# NUC400_v1 register map
File version: 1.0
Registers are 32-bit, read-write, reset 0x0 unless marked. A register's access mark holds for its fields unless they carry their own. Offsets are from the block's base; [hi:lo] are bit positions.

## CAP — CAP Register Map
Base 0x40030000
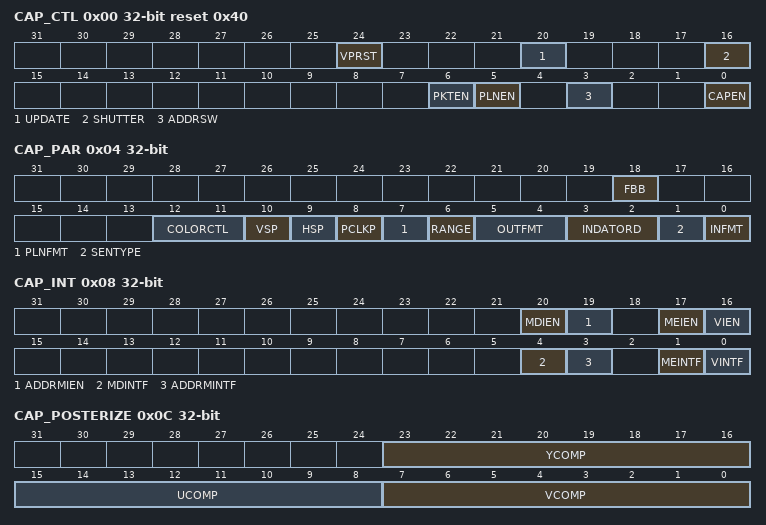
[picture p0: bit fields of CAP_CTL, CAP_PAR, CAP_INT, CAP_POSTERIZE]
0x00 CAP_CTL reset 0x40 — Image Capture Interface Control Register
  [24] VPRST — Capture Interface Reset
    0=Capture interface reset Disabled; 1=Capture interface reset Enabled
  [20] UPDATE — Update Register At New Frame
    0=Update register at new frame Disabled; 1=Update register at new frame Enabled (Auto clear to 0 when register updated)
  [16] SHUTTER — Image Capture Interface Automatically Disable The Capture Inteface After A Frame Had Been Captured
    0=Shutter Disabled; 1=Shutter Enabled
  [6] PKTEN — Packet Output Enable
    0=Packet output Disabled; 1=Packet output Enabled
  [5] PLNEN — Planar Output Enable
    0=Planar output Disabled; 1=Planar output Enabled
  [3] ADDRSW — Packet Buffer Address Switch
    0=Packet buffer address switch Disabled; 1=Packet buffer address switch Enabled
  [0] CAPEN — Image Capture Interface Enable
    0=Image Capture Interface Disabled; 1=Image Capture Interface Enabled
0x04 CAP_PAR — Image Capture Interface Parameter Register
  [18] FBB — Field By Blank. Hardware will tag field0 or field1 by vertical blanking instead of FIELD flag in ccir-656 mode.
    0=Field by blank Disabled; 1=Field by blank Enabled
  [12:11] COLORCTL — Special COLORCTL Processing
    0=Normal Color; 1=Sepia effect, corresponding U,V component value is set at register CAP_SEPIA; 2=Negative picture; 3=Posterize image, the Y, U, V components posterizing factor are set at register CAP_POSTERIZE
  [10] VSP — Sensor Vsync Polarity
    0=Sync Low; 1=Sync High
  [9] HSP — Sensor Hsync Polarity
    0=Sync Low; 1=Sync High
  [8] PCLKP — Sensor Pixel Clock Polarity
    0=Input video data and signals are latched by falling edge of Pixel Clock; 1=Input video data and signals are latched by rising edge of Pixel Clock
  [7] PLNFMT — Planar Output YUV Format
    0=YUV422; 1=YUV420
  [6] RANGE — Scale Input YUV CCIR601 Color Range To Full Range
    0=default; 1=Scale to full range
  [5:4] OUTFMT — Image Data Format Output To System Memory
    0=YCbCr422; 1=Only output Y; 2=RGB555; 3=RGB565
  [3:2] INDATORD — Sensor Input Data Order
    0=Y0 U0 Y1 V0; 1=Y0 V0 Y1 U0; 2=U0 Y0 V0 Y1; 3=V0 Y0 U0 Y1
  [1] SENTYPE — Sensor Input Type
    0=CCIR601; 1=CCIR656, VSync Hsync embedded in the data signal
  [0] INFMT — Sensor Input Data Format
    0=YCbCr422; 1=RGB565
0x08 CAP_INT — Image Capture Interface Interrupt Register
  [20] MDIEN — Motion Detection Output Finish Interrupt Enable
    0=CAP_MD finish interrupt Disabled; 1=CAP_MD finish interrupt Enabled
  [19] ADDRMIEN — Address Match Interrupt Enable
    0=Address match interrupt Disabled; 1=Address match interrupt Enabled
  [17] MEIEN — System Memory Error Interrupt Enable
    0=System memory error interrupt Disabled; 1=System memory error interrupt Enabled
  [16] VIEN — Video Frame End Interrupt Enable
    0=Video frame end interrupt Disabled; 1=Video frame end interrupt Enabled
  [4] MDINTF — Motion Detection Output Finish Interrupt. If this bit shows 1, Motion Detection Output Finish Interrupt occurred. Write 1 to clear it.
  [3] ADDRMINTF — Memory Address Match Interrupt. If this bit shows 1, Memory Address Match Interrupt occurred. Write 1 to clear it.
  [1] MEINTF — Bus Master Transfer Error Interrupt. If this bit shows 1, Transfer Error occurred. Write 1 to clear it.
  [0] VINTF — Video Frame End Interrupt. If this bit shows 1, receiving a frame completed. Write 1 to clear it.
0x0C CAP_POSTERIZE — YUV Component Posterizing Factor Register
  [23:16] YCOMP — Y Component Posterizing Factor
  [15:8] UCOMP — U Component Posterizing Factor
  [7:0] VCOMP — V Component Posterizing Factor
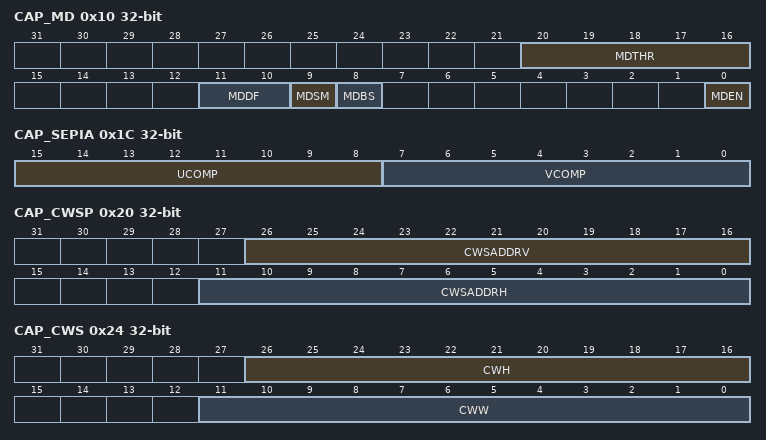
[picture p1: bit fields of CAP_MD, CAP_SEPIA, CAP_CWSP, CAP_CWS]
0x10 CAP_MD — Motion Detection Register
  [20:16] MDTHR — Motion Detection Differential Threshold
  [11:10] MDDF — Motion Detection Detect Frequency
    0=Each frame; 1=Every 2 frame; 2=Every 3 frame; 3=Every 4 frame
  [9] MDSM — Motion Detection Save Mode
    0=1 bit DIFF + 7 bit Y Differential; 1=1 bit DIFF only
  [8] MDBS — Motion Detection Block Size
    0=16x16; 1=8x8
  [0] MDEN — Motion Detection Enable
    0=CAP_MD Disabled; 1=CAP_MD Enabled
0x14 CAP_MDADDR — Motion Detection Output Address Register
  [31:0] MDADDR — Motion Detection Output Address Register (Word Alignment)
0x18 CAP_MDYADDR — Motion Detection Temp Y Output Address Register
  [31:0] MDYADDR — Motion Detection Temp Y Output Address Register (Word Alignment)
0x1C CAP_SEPIA — Sepia Effect Control Register
  [15:8] UCOMP — Define the constant U component while "Sepia" color effect is turned on.
  [7:0] VCOMP — Define the constant V component while "Sepia" color effect is turned on.
0x20 CAP_CWSP — Cropping Window Starting Address Register
  [26:16] CWSADDRV — Cropping Window Vertical Starting Address
  [11:0] CWSADDRH — Cropping Window Horizontal Starting Address
0x24 CAP_CWS — Cropping Window Size Register
  [26:16] CWH — Cropping Window Height
  [11:0] CWW — Cropping Window Width
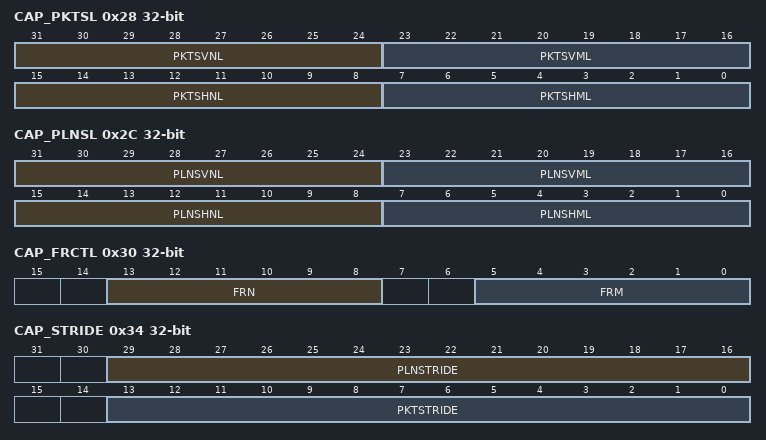
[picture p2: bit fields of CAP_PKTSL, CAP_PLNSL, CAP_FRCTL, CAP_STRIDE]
0x28 CAP_PKTSL — Packet Scaling Vertical/Horizontal Factor Register (LSB)
  [31:24] PKTSVNL — Packet Scaling Vertical Factor N (Lower 8-Bit). Specify the lower 8-bit of numerator part (N) of the vertical scaling factor. The lower 8-bit will be cascaded with higher 8-bit (PKDSVNH) to form a 16-bit numerator of vertical factor.
  [23:16] PKTSVML — Packet Scaling Vertical Factor M (Lower 8-Bit). Specify the lower 8-bit of denominator part (M) of the vertical scaling factor. The lower 8-bit will be cascaded with higher 8-bit (PKDSVMH) to form a 16-bit denominator (M) of vertical factor. The output image width will be equal to the image height * N/M. Note: The value of N must be equal to or less than M.
  [15:8] PKTSHNL — Packet Scaling Horizontal Factor N (Lower 8-Bit). Specify the lower 8-bit of numerator part (N) of the horizontal scaling factor. The lower 8-bit will be cascaded with higher 8-bit (PKDSHNH) to form a 16-bit numerator of horizontal factor.
  [7:0] PKTSHML — Packet Scaling Horizontal Factor M (Lower 8-Bit). Specifies the lower 8-bit of denominator part (M) of the horizontal scaling factor. The lower 8-bit will be cascaded with higher 8-bit (PKDSHMH) to form a 16-bit denominator (M) of vertical factor. The output image width will be equal to the image width * N/M. Note: The value of N must be equal to or less than M.
0x2C CAP_PLNSL — Planar Scaling Vertical/Horizontal Factor Register (LSB)
  [31:24] PLNSVNL — Planar Scaling Vertical Factor N (Lower 8-Bit). Specify the lower 8-bit of numerator part (N) of the vertical scaling factor. The lower 8-bit will be cascaded with higher 8-bit (PNDSVNH) to form a 16-bit numerator of vertical factor.
  [23:16] PLNSVML — Planar Scaling Vertical Factor M (Lower 8-Bit). Specify the lower 8-bit of denominator part (M) of the vertical scaling factor. The lower 8-bit will be cascaded with higher 8-bit (PNDSVMH) to form a 16-bit denominator (M) of vertical factor. The output image width will be equal to the image height * N/M. Note: The value of N must be equal to or less than M.
  [15:8] PLNSHNL — Planar Scaling Horizontal Factor N (Lower 8-Bit). Specify the lower 8-bit of numerator part (N) of the horizontal scaling factor. The lower 8-bit will be cascaded with higher 8-bit (PNDSHNH) to form a 16-bit numerator of horizontal factor.
  [7:0] PLNSHML — Planar Scaling Horizontal Factor M (Lower 8-Bit). Specify the lower 8-bit of denominator part (M) of the horizontal scaling factor. The lower 8-bit will be cascaded with higher 8-bit (PNDSHMH) to form a 16-bit denominator (M) of vertical factor. The output image width will be equal to the image width * N/M. Note: The value of N must be equal to or less than M.
0x30 CAP_FRCTL — Scaling Frame Rate Factor Register
  [13:8] FRN — Scaling Frame Rate Factor N. Specify the denominator part (N) of the frame rate scaling factor.
  [5:0] FRM — Scaling Frame Rate Factor M. Specify the denominator part (M) of the frame rate scaling factor. The output image frame rate will be equal to input image frame rate * (N/M). Note: The value of N must be equal to or less than M.
0x34 CAP_STRIDE — Frame Output Pixel Stride Width Register
  [29:16] PLNSTRIDE — Planar Frame Output Pixel Stride Width. The output pixel stride size of planar pipe.
  [13:0] PKTSTRIDE — Packet Frame Output Pixel Stride Width. The output pixel stride size of packet pipe.
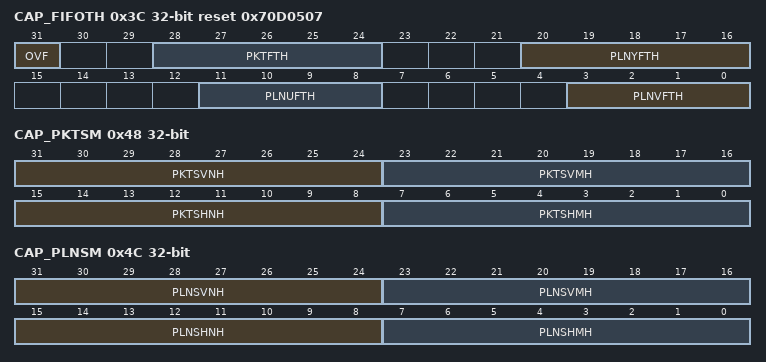
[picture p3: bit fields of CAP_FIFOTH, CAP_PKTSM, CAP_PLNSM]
0x3C CAP_FIFOTH reset 0x70D0507 — FIFO Threshold Register
  [31] OVF — FIFO Overflow Flag
  [28:24] PKTFTH — Packet FIFO Threshold
  [20:16] PLNYFTH — Planar Y FIFO Threshold
  [11:8] PLNUFTH — Planar U FIFO Threshold
  [3:0] PLNVFTH — Planar V FIFO Threshold
0x40 CAP_CMPADDR reset 0xFFFFFFFC — Compare Memory Base Address Register
  [31:0] CMPADDR — Compare Memory Base Address. Word aligns address; ignore the bits [1:0].
0x48 CAP_PKTSM — Packet Scaling Vertical/Horizontal Factor Register (MSB)
  [31:24] PKTSVNH — Packet Scaling Vertical Factor N (Higher 8-Bit). Specify the higher 8-bit of numerator part (N) of the vertical scaling factor. Please refer to the register "CAP_PKTSL" to check the cooperation between these two registers.
  [23:16] PKTSVMH — Packet Scaling Vertical Factor M (Higher 8-Bit). Specify the lower 8-bit of denominator part (M) of the vertical scaling factor. Please refer to the register "CAP_PKTSL" to check the cooperation between these two registers.
  [15:8] PKTSHNH — Packet Scaling Horizontal Factor N (Higher 8-Bit). Specify the lower 8-bit of numerator part (N) of the horizontal scaling factor. Please refer to the register "CAP_PKTSL" for the detailed operation.
  [7:0] PKTSHMH — Packet Scaling Horizontal Factor M (Higher 8-Bit). Specify the lower 8-bit of denominator part (M) of the horizontal scaling factor. Please refer to the register "CAP_PKTSL" for the detailed operation.
0x4C CAP_PLNSM — Planar Scaling Vertical/Horizontal Factor Register (MSB)
  [31:24] PLNSVNH — Planar Scaling Vertical Factor N (Higher 8-Bit). Specifies the higher 8-bit of numerator part (N) of the vertical scaling factor. For detailed programming, please refer to the register "CAP_PLNSL".
  [23:16] PLNSVMH — Planar Scaling Vertical Factor M (Higher 8-Bit). Specifies the lower 8-bit of denominator part (M) of the vertical scaling factor. For detailed programming, please refer to the register "CAP_PLNSL".
  [15:8] PLNSHNH — Planar Scaling Horizontal Factor N (Higher 8-Bit). Specifies the higher 8-bit of numerator part (N) of the horizontal scaling factor. For detailed programming, please refer to the register "CAP_PLNSL".
  [7:0] PLNSHMH — Planar Scaling Horizontal Factor M (Higher 8-Bit). Specifies the higher 8-bit of denominator part (M) of the horizontal scaling factor. For detailed programming, please refer to the register "CAP_PLNSL".
0x50 CAP_CURADDRP ro — Current Packet System Memory Address Register
  [31:0] CURADDR — Current Packet Output Memory Address
0x54 CAP_CURADDRY ro — Current Planar Y System Memory Address Register
  [31:0] CURADDR — Current Planar Y Output Memory Address
0x58 CAP_CURADDRU ro — Current Planar U System Memory Address Register
  [31:0] CURADDR — Current Planar U Output Memory Address
0x5C CAP_CURVADDR ro — Current Planar V System Memory Address Register
  [31:0] CURADDR — Current Planar V Output Memory Address
0x60 CAP_PKTBA0 — System Memory Packet Base Address 0 Register
  [31:0] BASEADDR — System Memory Packet Base Address 0. Word aligns address; ignore the bits [1:0].
0x64 CAP_PKTBA1 — System Memory Packet Base Address 1 Register
  [31:0] BASEADDR — System Memory Packet Base Address 1. Word aligns address; ignore the bits [1:0].
0x80 CAP_YBA — System Memory Planar Y Base Address Register
  [31:0] BASEADDR — System Memory Planar Y Base Address. Word aligns address; ignore the bits [1:0].
0x84 CAP_UBA — System Memory Planar U Base Address Register
  [31:0] BASEADDR — System Memory Planar U Base Address. Word aligns address; ignore the bits [1:0].
0x88 CAP_VBA — System Memory Planar V Base Address Register
  [31:0] BASEADDR — System Memory Planar V Base Address. Word aligns address; ignore the bits [1:0].
